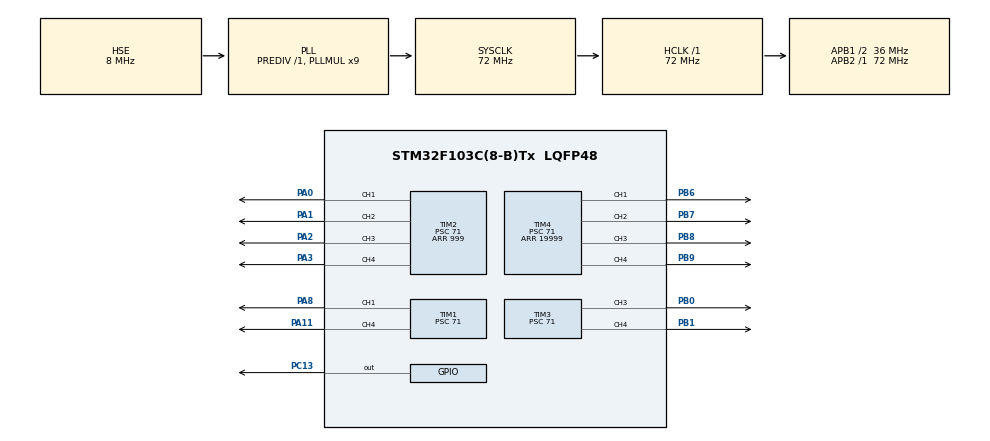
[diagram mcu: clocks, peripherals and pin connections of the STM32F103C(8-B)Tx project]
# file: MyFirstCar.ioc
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Mcu.Family=STM32F1
Mcu.Name=STM32F103C(8-B)Tx
Mcu.Package=LQFP48
NVIC.PriorityGroup=NVIC_PRIORITYGROUP_4
PA0-WKUP.Signal=S_TIM2_CH1_ETR
PA1.Signal=S_TIM2_CH2
PA11.Signal=S_TIM1_CH4
PA13.Mode=Serial_Wire
PA13.Signal=SYS_JTMS-SWDIO
PA14.Mode=Serial_Wire
PA14.Signal=SYS_JTCK-SWCLK
PA2.Signal=S_TIM2_CH3
PA3.Signal=S_TIM2_CH4
PA8.Signal=S_TIM1_CH1
PB0.Signal=S_TIM3_CH3
PB1.Signal=S_TIM3_CH4
PB6.Signal=S_TIM4_CH1
PB7.Signal=S_TIM4_CH2
PB8.Signal=S_TIM4_CH3
PB9.Signal=S_TIM4_CH4
PC13-TAMPER-RTC.Signal=GPIO_Output
PD0-OSC_IN.Mode=HSE-External-Oscillator
PD0-OSC_IN.Signal=RCC_OSC_IN
PD1-OSC_OUT.Mode=HSE-External-Oscillator
PD1-OSC_OUT.Signal=RCC_OSC_OUT
ProjectManager.HeapSize=0x200
ProjectManager.StackSize=0x400
ProjectManager.TargetToolchain=CMake
RCC.AHBFreq_Value=72000000
RCC.APB1CLKDivider=RCC_HCLK_DIV2
RCC.APB1Freq_Value=36000000
RCC.APB1TimFreq_Value=72000000
RCC.APB2Freq_Value=72000000
RCC.APB2TimFreq_Value=72000000
RCC.HCLKFreq_Value=72000000
RCC.PLLMUL=RCC_PLL_MUL9
RCC.PLLSourceVirtual=RCC_PLLSOURCE_HSE
RCC.SYSCLKFreq_VALUE=72000000
RCC.SYSCLKSource=RCC_SYSCLKSOURCE_PLLCLK
RCC.USBFreq_Value=72000000
SH.S_TIM1_CH1.0=TIM1_CH1,PWM Generation1 CH1
SH.S_TIM1_CH4.0=TIM1_CH4,PWM Generation4 CH4
SH.S_TIM2_CH1_ETR.0=TIM2_CH1,PWM Generation1 CH1
SH.S_TIM2_CH2.0=TIM2_CH2,PWM Generation2 CH2
SH.S_TIM2_CH3.0=TIM2_CH3,PWM Generation3 CH3
SH.S_TIM2_CH4.0=TIM2_CH4,PWM Generation4 CH4
SH.S_TIM3_CH3.0=TIM3_CH3,PWM Generation3 CH3
SH.S_TIM3_CH4.0=TIM3_CH4,PWM Generation4 CH4
SH.S_TIM4_CH1.0=TIM4_CH1,PWM Generation1 CH1
SH.S_TIM4_CH2.0=TIM4_CH2,PWM Generation2 CH2
SH.S_TIM4_CH3.0=TIM4_CH3,PWM Generation3 CH3
SH.S_TIM4_CH4.0=TIM4_CH4,PWM Generation4 CH4
TIM1.AutoReloadPreload=TIM_AUTORELOAD_PRELOAD_ENABLE
TIM1.Channel-PWM\ Generation1\ CH1=TIM_CHANNEL_1
TIM1.Channel-PWM\ Generation4\ CH4=TIM_CHANNEL_4
TIM1.Period=999
TIM1.Prescaler=71
TIM2.AutoReloadPreload=TIM_AUTORELOAD_PRELOAD_ENABLE
TIM2.Channel-PWM\ Generation1\ CH1=TIM_CHANNEL_1
TIM2.Channel-PWM\ Generation2\ CH2=TIM_CHANNEL_2
TIM2.Channel-PWM\ Generation3\ CH3=TIM_CHANNEL_3
TIM2.Channel-PWM\ Generation4\ CH4=TIM_CHANNEL_4
TIM2.Period=999
TIM2.Prescaler=71
TIM2.Pulse-PWM\ Generation1\ CH1=0
TIM3.AutoReloadPreload=TIM_AUTORELOAD_PRELOAD_ENABLE
TIM3.Channel-PWM\ Generation3\ CH3=TIM_CHANNEL_3
TIM3.Channel-PWM\ Generation4\ CH4=TIM_CHANNEL_4
TIM3.Period=999
TIM3.Prescaler=71
TIM3.Pulse-PWM\ Generation3\ CH3=0
TIM4.AutoReloadPreload=TIM_AUTORELOAD_PRELOAD_ENABLE
TIM4.Channel-PWM\ Generation1\ CH1=TIM_CHANNEL_1
TIM4.Channel-PWM\ Generation2\ CH2=TIM_CHANNEL_2
TIM4.Channel-PWM\ Generation3\ CH3=TIM_CHANNEL_3
TIM4.Channel-PWM\ Generation4\ CH4=TIM_CHANNEL_4
TIM4.Period=19999
TIM4.Prescaler=71
TIM4.Pulse-PWM\ Generation1\ CH1=0
TIM4.Pulse-PWM\ Generation2\ CH2=0
TIM4.Pulse-PWM\ Generation3\ CH3=0
TIM4.Pulse-PWM\ Generation4\ CH4=0
VP_TIM1_VS_ClockSourceINT.Mode=Internal
VP_TIM2_VS_ClockSourceINT.Mode=Internal
VP_TIM3_VS_ClockSourceINT.Mode=Internal
VP_TIM4_VS_ClockSourceINT.Mode=Internal
board=custom

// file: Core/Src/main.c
/* USER CODE BEGIN Header */
/**
  ******************************************************************************
  * @file           : main.c
  * @brief          : Main program body
  ******************************************************************************
  * @attention
  *
  * Copyright (c) 2026 STMicroelectronics.
  * All rights reserved.
  *
  * This software is licensed under terms that can be found in the LICENSE file
  * in the root directory of this software component.
  * If no LICENSE file comes with this software, it is provided AS-IS.
  *
  ******************************************************************************
  */
/* USER CODE END Header */
#include "main.h"

/* USER CODE BEGIN Includes */
#include "app.h"
/* USER CODE END Includes */

TIM_HandleTypeDef htim1;
TIM_HandleTypeDef htim2;
TIM_HandleTypeDef htim3;
TIM_HandleTypeDef htim4;

void SystemClock_Config(void);
static void MX_GPIO_Init(void);
static void MX_TIM1_Init(void);
static void MX_TIM2_Init(void);
static void MX_TIM3_Init(void);
static void MX_TIM4_Init(void);

int main(void)
{

  /* MCU Configuration--------------------------------------------------------*/

  /* Reset of all peripherals, Initializes the Flash interface and the Systick. */
  HAL_Init();

  /* Configure the system clock */
  SystemClock_Config();

  /* Initialize all configured peripherals */
  MX_GPIO_Init();
  MX_TIM1_Init();
  MX_TIM2_Init();
  MX_TIM3_Init();
  MX_TIM4_Init();
  /* USER CODE BEGIN 2 */
  app_init();
  /* USER CODE END 2 */

  /* Infinite loop */
  while (1)
  {

    /* USER CODE BEGIN 3 */
    app_task();
  }
  /* USER CODE END 3 */
}

void SystemClock_Config(void)
{
  RCC_OscInitTypeDef RCC_OscInitStruct = {0};
  RCC_ClkInitTypeDef RCC_ClkInitStruct = {0};

  /** Initializes the RCC Oscillators according to the specified parameters
  * in the RCC_OscInitTypeDef structure.
  */
  RCC_OscInitStruct.OscillatorType = RCC_OSCILLATORTYPE_HSE;
  RCC_OscInitStruct.HSEState = RCC_HSE_ON;
  RCC_OscInitStruct.HSEPredivValue = RCC_HSE_PREDIV_DIV1;
  RCC_OscInitStruct.HSIState = RCC_HSI_ON;
  RCC_OscInitStruct.PLL.PLLState = RCC_PLL_ON;
  RCC_OscInitStruct.PLL.PLLSource = RCC_PLLSOURCE_HSE;
  RCC_OscInitStruct.PLL.PLLMUL = RCC_PLL_MUL9;
  if (HAL_RCC_OscConfig(&RCC_OscInitStruct) != HAL_OK)
  {
    Error_Handler();
  }

  /** Initializes the CPU, AHB and APB buses clocks
  */
  RCC_ClkInitStruct.ClockType = RCC_CLOCKTYPE_HCLK|RCC_CLOCKTYPE_SYSCLK
                              |RCC_CLOCKTYPE_PCLK1|RCC_CLOCKTYPE_PCLK2;
  RCC_ClkInitStruct.SYSCLKSource = RCC_SYSCLKSOURCE_PLLCLK;
  RCC_ClkInitStruct.AHBCLKDivider = RCC_SYSCLK_DIV1;
  RCC_ClkInitStruct.APB1CLKDivider = RCC_HCLK_DIV2;
  RCC_ClkInitStruct.APB2CLKDivider = RCC_HCLK_DIV1;

  if (HAL_RCC_ClockConfig(&RCC_ClkInitStruct, FLASH_LATENCY_2) != HAL_OK)
  {
    Error_Handler();
  }
}

static void MX_TIM1_Init(void)
{

  TIM_ClockConfigTypeDef sClockSourceConfig = {0};
  TIM_MasterConfigTypeDef sMasterConfig = {0};
  TIM_OC_InitTypeDef sConfigOC = {0};
  TIM_BreakDeadTimeConfigTypeDef sBreakDeadTimeConfig = {0};

  htim1.Instance = TIM1;
  htim1.Init.Prescaler = 71;
  htim1.Init.CounterMode = TIM_COUNTERMODE_UP;
  htim1.Init.Period = 49;          /* 20kHz：72MHz / 72 / (49+1)，见 motor.h */
  htim1.Init.ClockDivision = TIM_CLOCKDIVISION_DIV1;
  htim1.Init.RepetitionCounter = 0;
  htim1.Init.AutoReloadPreload = TIM_AUTORELOAD_PRELOAD_ENABLE;
  if (HAL_TIM_Base_Init(&htim1) != HAL_OK)
  {
    Error_Handler();
  }
  sClockSourceConfig.ClockSource = TIM_CLOCKSOURCE_INTERNAL;
  if (HAL_TIM_ConfigClockSource(&htim1, &sClockSourceConfig) != HAL_OK)
  {
    Error_Handler();
  }
  if (HAL_TIM_PWM_Init(&htim1) != HAL_OK)
  {
    Error_Handler();
  }
  sMasterConfig.MasterOutputTrigger = TIM_TRGO_RESET;
  sMasterConfig.MasterSlaveMode = TIM_MASTERSLAVEMODE_DISABLE;
  if (HAL_TIMEx_MasterConfigSynchronization(&htim1, &sMasterConfig) != HAL_OK)
  {
    Error_Handler();
  }
  sConfigOC.OCMode = TIM_OCMODE_PWM1;
  sConfigOC.Pulse = 0;
  sConfigOC.OCPolarity = TIM_OCPOLARITY_HIGH;
  sConfigOC.OCNPolarity = TIM_OCNPOLARITY_HIGH;
  sConfigOC.OCFastMode = TIM_OCFAST_DISABLE;
  sConfigOC.OCIdleState = TIM_OCIDLESTATE_RESET;
  sConfigOC.OCNIdleState = TIM_OCNIDLESTATE_RESET;
  if (HAL_TIM_PWM_ConfigChannel(&htim1, &sConfigOC, TIM_CHANNEL_1) != HAL_OK)
  {
    Error_Handler();
  }
  if (HAL_TIM_PWM_ConfigChannel(&htim1, &sConfigOC, TIM_CHANNEL_4) != HAL_OK)
  {
    Error_Handler();
  }
  sBreakDeadTimeConfig.OffStateRunMode = TIM_OSSR_DISABLE;
  sBreakDeadTimeConfig.OffStateIDLEMode = TIM_OSSI_DISABLE;
  sBreakDeadTimeConfig.LockLevel = TIM_LOCKLEVEL_OFF;
  sBreakDeadTimeConfig.DeadTime = 0;
  sBreakDeadTimeConfig.BreakState = TIM_BREAK_DISABLE;
  sBreakDeadTimeConfig.BreakPolarity = TIM_BREAKPOLARITY_HIGH;
  sBreakDeadTimeConfig.AutomaticOutput = TIM_AUTOMATICOUTPUT_DISABLE;
  if (HAL_TIMEx_ConfigBreakDeadTime(&htim1, &sBreakDeadTimeConfig) != HAL_OK)
  {
    Error_Handler();
  }
  HAL_TIM_MspPostInit(&htim1);

}

static void MX_TIM2_Init(void)
{

  TIM_ClockConfigTypeDef sClockSourceConfig = {0};
  TIM_MasterConfigTypeDef sMasterConfig = {0};
  TIM_OC_InitTypeDef sConfigOC = {0};

  htim2.Instance = TIM2;
  htim2.Init.Prescaler = 71;
  htim2.Init.CounterMode = TIM_COUNTERMODE_UP;
  htim2.Init.Period = 49;          /* 20kHz：72MHz / 72 / (49+1)，见 motor.h */
  htim2.Init.ClockDivision = TIM_CLOCKDIVISION_DIV1;
  htim2.Init.AutoReloadPreload = TIM_AUTORELOAD_PRELOAD_ENABLE;
  if (HAL_TIM_Base_Init(&htim2) != HAL_OK)
  {
    Error_Handler();
  }
  sClockSourceConfig.ClockSource = TIM_CLOCKSOURCE_INTERNAL;
  if (HAL_TIM_ConfigClockSource(&htim2, &sClockSourceConfig) != HAL_OK)
  {
    Error_Handler();
  }
  if (HAL_TIM_PWM_Init(&htim2) != HAL_OK)
  {
    Error_Handler();
  }
  sMasterConfig.MasterOutputTrigger = TIM_TRGO_RESET;
  sMasterConfig.MasterSlaveMode = TIM_MASTERSLAVEMODE_DISABLE;
  if (HAL_TIMEx_MasterConfigSynchronization(&htim2, &sMasterConfig) != HAL_OK)
  {
    Error_Handler();
  }
  sConfigOC.OCMode = TIM_OCMODE_PWM1;
  sConfigOC.Pulse = 0;
  sConfigOC.OCPolarity = TIM_OCPOLARITY_HIGH;
  sConfigOC.OCFastMode = TIM_OCFAST_DISABLE;
  if (HAL_TIM_PWM_ConfigChannel(&htim2, &sConfigOC, TIM_CHANNEL_1) != HAL_OK)
  {
    Error_Handler();
  }
  if (HAL_TIM_PWM_ConfigChannel(&htim2, &sConfigOC, TIM_CHANNEL_2) != HAL_OK)
  {
    Error_Handler();
  }
  if (HAL_TIM_PWM_ConfigChannel(&htim2, &sConfigOC, TIM_CHANNEL_3) != HAL_OK)
  {
    Error_Handler();
  }
  if (HAL_TIM_PWM_ConfigChannel(&htim2, &sConfigOC, TIM_CHANNEL_4) != HAL_OK)
  {
    Error_Handler();
  }
  HAL_TIM_MspPostInit(&htim2);

}

static void MX_TIM3_Init(void)
{

  TIM_ClockConfigTypeDef sClockSourceConfig = {0};
  TIM_MasterConfigTypeDef sMasterConfig = {0};
  TIM_OC_InitTypeDef sConfigOC = {0};

  htim3.Instance = TIM3;
  htim3.Init.Prescaler = 71;
  htim3.Init.CounterMode = TIM_COUNTERMODE_UP;
  htim3.Init.Period = 49;          /* 20kHz：72MHz / 72 / (49+1)，见 motor.h */
  htim3.Init.ClockDivision = TIM_CLOCKDIVISION_DIV1;
  htim3.Init.AutoReloadPreload = TIM_AUTORELOAD_PRELOAD_ENABLE;
  if (HAL_TIM_Base_Init(&htim3) != HAL_OK)
  {
    Error_Handler();
  }
  sClockSourceConfig.ClockSource = TIM_CLOCKSOURCE_INTERNAL;
  if (HAL_TIM_ConfigClockSource(&htim3, &sClockSourceConfig) != HAL_OK)
  {
    Error_Handler();
  }
  if (HAL_TIM_PWM_Init(&htim3) != HAL_OK)
  {
    Error_Handler();
  }
  sMasterConfig.MasterOutputTrigger = TIM_TRGO_RESET;
  sMasterConfig.MasterSlaveMode = TIM_MASTERSLAVEMODE_DISABLE;
  if (HAL_TIMEx_MasterConfigSynchronization(&htim3, &sMasterConfig) != HAL_OK)
  {
    Error_Handler();
  }
  sConfigOC.OCMode = TIM_OCMODE_PWM1;
  sConfigOC.Pulse = 0;
  sConfigOC.OCPolarity = TIM_OCPOLARITY_HIGH;
  sConfigOC.OCFastMode = TIM_OCFAST_DISABLE;
  if (HAL_TIM_PWM_ConfigChannel(&htim3, &sConfigOC, TIM_CHANNEL_3) != HAL_OK)
  {
    Error_Handler();
  }
  if (HAL_TIM_PWM_ConfigChannel(&htim3, &sConfigOC, TIM_CHANNEL_4) != HAL_OK)
  {
    Error_Handler();
  }
  HAL_TIM_MspPostInit(&htim3);

}

static void MX_TIM4_Init(void)
{

  TIM_ClockConfigTypeDef sClockSourceConfig = {0};
  TIM_MasterConfigTypeDef sMasterConfig = {0};
  TIM_OC_InitTypeDef sConfigOC = {0};

  htim4.Instance = TIM4;
  htim4.Init.Prescaler = 71;
  htim4.Init.CounterMode = TIM_COUNTERMODE_UP;
  htim4.Init.Period = 19999;
  htim4.Init.ClockDivision = TIM_CLOCKDIVISION_DIV1;
  htim4.Init.AutoReloadPreload = TIM_AUTORELOAD_PRELOAD_ENABLE;
  if (HAL_TIM_Base_Init(&htim4) != HAL_OK)
  {
    Error_Handler();
  }
  sClockSourceConfig.ClockSource = TIM_CLOCKSOURCE_INTERNAL;
  if (HAL_TIM_ConfigClockSource(&htim4, &sClockSourceConfig) != HAL_OK)
  {
    Error_Handler();
  }
  if (HAL_TIM_PWM_Init(&htim4) != HAL_OK)
  {
    Error_Handler();
  }
  sMasterConfig.MasterOutputTrigger = TIM_TRGO_RESET;
  sMasterConfig.MasterSlaveMode = TIM_MASTERSLAVEMODE_DISABLE;
  if (HAL_TIMEx_MasterConfigSynchronization(&htim4, &sMasterConfig) != HAL_OK)
  {
    Error_Handler();
  }
  sConfigOC.OCMode = TIM_OCMODE_PWM1;
  sConfigOC.OCPolarity = TIM_OCPOLARITY_HIGH;
  sConfigOC.OCFastMode = TIM_OCFAST_DISABLE;

  sConfigOC.Pulse = 1500;    /* 大臂中位 */
  if (HAL_TIM_PWM_ConfigChannel(&htim4, &sConfigOC, TIM_CHANNEL_1) != HAL_OK)
  {
    Error_Handler();
  }
  sConfigOC.Pulse = 1500;    /* 小臂中位 */
  if (HAL_TIM_PWM_ConfigChannel(&htim4, &sConfigOC, TIM_CHANNEL_2) != HAL_OK)
  {
    Error_Handler();
  }
  sConfigOC.Pulse = 1000;    /* 夹爪上电张开，不要顶死 */
  if (HAL_TIM_PWM_ConfigChannel(&htim4, &sConfigOC, TIM_CHANNEL_3) != HAL_OK)
  {
    Error_Handler();
  }
  sConfigOC.Pulse = 1500;    /* 预留第 4 个舵机 */
  if (HAL_TIM_PWM_ConfigChannel(&htim4, &sConfigOC, TIM_CHANNEL_4) != HAL_OK)
  {
    Error_Handler();
  }
  HAL_TIM_MspPostInit(&htim4);

}

static void MX_GPIO_Init(void)
{
  GPIO_InitTypeDef GPIO_InitStruct = {0};

  /* GPIO Ports Clock Enable */
  __HAL_RCC_GPIOC_CLK_ENABLE();
  __HAL_RCC_GPIOD_CLK_ENABLE();
  __HAL_RCC_GPIOA_CLK_ENABLE();
  __HAL_RCC_GPIOB_CLK_ENABLE();

  /*Configure GPIO pin Output Level */
  HAL_GPIO_WritePin(GPIOC, GPIO_PIN_13, GPIO_PIN_RESET);

  /*Configure GPIO pin : PC13 */
  GPIO_InitStruct.Pin = GPIO_PIN_13;
  GPIO_InitStruct.Mode = GPIO_MODE_OUTPUT_PP;
  GPIO_InitStruct.Pull = GPIO_NOPULL;
  GPIO_InitStruct.Speed = GPIO_SPEED_FREQ_LOW;
  HAL_GPIO_Init(GPIOC, &GPIO_InitStruct);

}

void Error_Handler(void)
{
  __disable_irq();
  while (1)
  {
  }
}
